# psc3_p8_ppca register map
Vendor: Infineon Technologies; Series: PSC3_P8; File version: 1.0
CPU: CM33 r0p1, little endian, MPU, FPU, DSP, VTOR, 3 interrupt priority bits, 143 interrupts
Registers are 32-bit, read-write, reset 0x0 unless marked. A register's access mark holds for its fields unless they carry their own. Offsets are from the block's base; [hi:lo] are bit positions; lines under a group give offsets from that group; {n}, {i} and the like mark numbered series; 'fields as' and 'values as' point back to an identical list; <NAME> marks a mode.

## PPCA_ATOPSS_DCSG_GRP0
Base 0x43588000
Same registers: PPCA_ATOPSS_DCSG_GRP1 0x4358A000
0x00 DCSG group
  {0x0+0x100*j} SLICE[{j}] (j=0..5) group — DCSG Slice Module
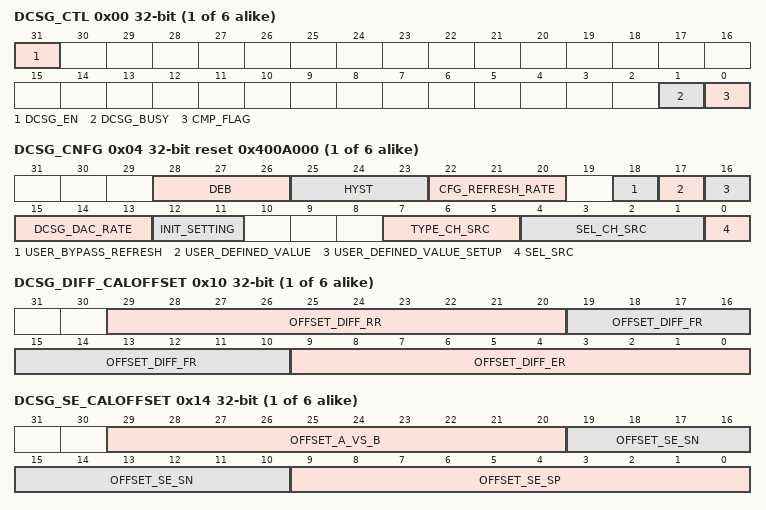
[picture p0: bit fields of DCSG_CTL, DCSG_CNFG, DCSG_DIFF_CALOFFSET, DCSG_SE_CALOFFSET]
    0x00 DCSG_CTL — Analog Comparator Control Register
      [31] DCSG_EN — Enable/Disable Analog Comparator 0 = Disable (power down) 1 = Enable
      [1] DCSG_BUSY ro — DCSG Busy: 1 = Busy 0 = Idle
      [0] CMP_FLAG ro — Reflects status of the COMP_OUT signal 0 = Input <= Configured Threshold 1 = Input > Configured Threshold
    0x04 DCSG_CNFG reset 0x400A000 — Analog Comparator Configuration Register
      [28:26] DEB — Debounce feature for HYST operation (Only for A_VS_B Mode Hysteresis )
        0=Debounce feature is disabled; 1=Transistion must be valid for 2 clock cycle; {v}=Transition must be valid for {v+1} clock cycle (v=2..7)
      [25:23] HYST — Hysteresis setup for A_VS_B Mode. 1 LSB is equivalent to 1.6mV
        0=Hysteresis feature is disabled; 1=+/- 1 LSB hysteresis is introduced; 2=+/- 2 LSB hysteresis is introduced; 3=+/- 4 LSB hysteresis is introduced; 4=+/- 8 LSB hysteresis is introduced; 5=+/- 16 LSB hysteresis is introduced; 6=+/- 32 LSB hysteresis is introduced; 7=+/- 64 LSB hysteresis is introduced
      [22:20] CFG_REFRESH_RATE — Refresh Rate Setting for Internal INIT. To compute the refresh rate duration, please use the following formula. 1/DCSG_CLK*Clk counter value
        0=10000 Clk counter -> 50.0usec based on 200MHz Clock; 1=7500 Clk counter -> 37.5usec based on 200MHz Clock; 2=5000 Clk counter -> 25.0usec based on 200MHz Clock; 3=3500 Clk counter -> 17.5usec based on 200MHz Clock; 4=2500 Clk counter -> 12.5usec based on 200MHz Clock; 5=1750 Clk counter -> 8.75usec based on 200MHz Clock; 6=1250 Clk counter -> 6.25usec based on 200MHz Clock; 7=1000 Clk counter -> 5.00usec based on 200MHz Clock
      [18] USER_BYPASS_REFRESH — BYPASS_REFRESH 0 - No Bypass 1 - Bypass. When bypass and in USER_DEFINED_VALUE_SETUP, USER defined value will be drive the CMP_FLAG
      [17] USER_DEFINED_VALUE
      [16] USER_DEFINED_VALUE_SETUP — To use User Defined Value during Refresh 0 - CMP_FLAG from comparator output 1 - CMP_FLAG from user default value
      [15:13] DCSG_DAC_RATE — To configurate the DCSG DAC update rate (Based on 200MHz Clock) 0 - 4 Clock Cycle, 0 tblank clk cycle (This is only for slope gen only) 1 - 4 Clock Cycle, 2 tblank clk cycle (This is only for slope gen only) 2 - 4 Clock Cycle, 3 tblank clk cycle (This is only for slope gen only) 3 - 6 Clock Cycle, 4 tblank clk cycle 4 - 8 Clock Cycle, 6 tblank clk cycle 5 - 10 Clock Cycle, 8 tblank clk cycle 6 - 12 Clock Cycle, 10 tblank clk cycle 7 - 20 Clock Cycle, 18 tblank clk cycle
      [12:11] INIT_SETTING — To configure the blanking period of DCSG during initization
        0=BLANK_8 (Blanking period is 8 after init. It will be 98 if used with SEL_SRC=1); 1=BLANK_10_1 (Blanking period is 10 after init. It will be 98 if used with SEL_SRC=1); 2=BLANK_10_2 (Blanking period is 10 after init. It will be 98 if used with SEL_SRC=1); 3=BLANK_12 (Blanking period is 12 after init. It will be 98 if used with SEL_SRC=1)
      [7:5] TYPE_CH_SRC — Select between Differential or Single Ended or A_vs_B
        0=TYPE_CH_DIFF_ER (Differential Mode Full Range support +/-3.3V. Other than 5, this will be selected); 1=TYPE_CH_DIFF_FR (Differential Mode Full Range support 0-3.3V); 2=TYPE_CH_SINGLE_P (Single-Ended Mode P Vs GND (Use together with SEL_CH_SRC)); 3=TYPE_CH_SINGLE_N (Single-Ended Mode N Vs GND (User together with SEL_CH_SRC)); 4=TYPE_CH_DIFF_RR (Differential Mode Full Range support +/-200mV); 5=TYPE_CH_A_vs_B (A vs B Mode)
      [4:1] SEL_CH_SRC — Select Analog Input Channel Source 0 = CH 0 1 = CH 1 ... 11 = CH 11
      [0] SEL_SRC — Select between Internal (DAC R2R) or External Source (Analog input Channel) 0 = External (From Analog Input Pad) 1 = Internal (From DAC R2R Output)
    0x08 DCSG_TH — Analog Comparator Threshold configuration register
      [11:0] TH — DCSG Threshold register. User shall ensure that DCSG_BUSY bit is '0' when performing write operation on this register. Please take note that if user is using SLGEN, user should observe the DCSG_SLGEN_CTL.SLGEN_BUSY.
    0x10 DCSG_DIFF_CALOFFSET — Analog Comparator Differential Mode Calibration register
      [29:20] OFFSET_DIFF_RR — Signed offset calibration value for sampler in differential mode in DIFF_RR
      [19:10] OFFSET_DIFF_FR — Signed offset calibration value for sampler in differential mode in DIFF_FR
      [9:0] OFFSET_DIFF_ER — Signed offset calibration value for sampler in differential mode in DIFF_ER
    0x14 DCSG_SE_CALOFFSET — Analog Comparator Single Ended Mode Calibration register
      [29:20] OFFSET_A_VS_B — Signed offset calibration value for sampler in A vs B mode
      [19:10] OFFSET_SE_SN — Signed offset calibration value for sampler in single ended N mode
      [9:0] OFFSET_SE_SP — Signed offset calibration value for sampler in single ended P mode
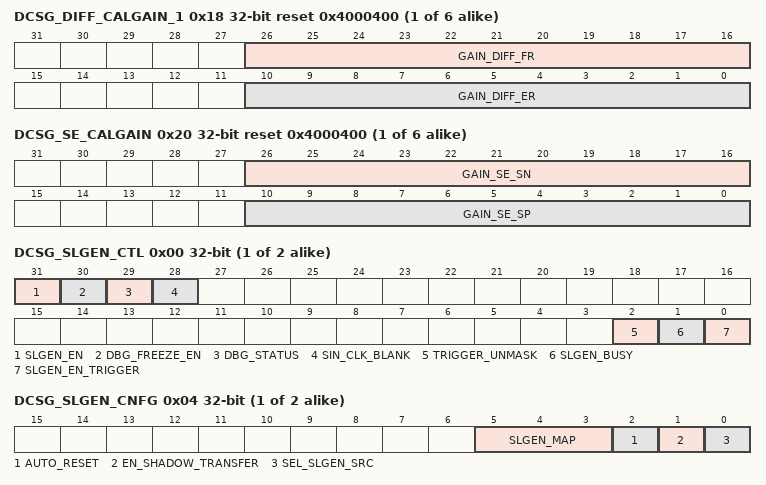
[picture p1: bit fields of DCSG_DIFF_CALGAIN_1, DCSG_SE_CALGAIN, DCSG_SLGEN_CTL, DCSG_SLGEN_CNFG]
    0x18 DCSG_DIFF_CALGAIN_1 reset 0x4000400 — Analog Comparator Differential Mode Gain register
      [26:16] GAIN_DIFF_FR — Signed gain calibration value for sampler in differential mode in DIFF_FR
      [10:0] GAIN_DIFF_ER — Signed gain calibration value for sampler in differential mode in DIFF_ER
    0x1C DCSG_DIFF_CALGAIN_2 reset 0x400 — Analog Comparator Differential Mode Gain register
      [10:0] GAIN_DIFF_RR — Signed gain calibration value for sampler in differential mode in DIFF_RR
    0x20 DCSG_SE_CALGAIN reset 0x4000400 — Analog Comparator Single Ended Mode Gain register
      [26:16] GAIN_SE_SN — Signed gain calibration value for sampler in single ended N mode
      [10:0] GAIN_SE_SP — Signed gain calibration value for sampler in single ended P mode
  {0x600+0x100*j} SLGEN[{j}] (j=0..1) group — DCSG Slice Module
    0x00 DCSG_SLGEN_CTL
      [31] SLGEN_EN — Enable/Disable Slope Generator 0 = Disable (under reset) 1 = Enable
      [30] DBG_FREEZE_EN — Specifies the slope generator behavior in debug mode. '0': When ='0', slope generator operation continues or resume '1': When ='1', slope generator freeze the operation immediately
      [29] DBG_STATUS ro — Specifies whether SLGEN has enter into Debug state 1 = Yes 2 = No
      [28] SIN_CLK_BLANK — Single Clock Blank 0 - Enabled 1 - Disabled
      [2] TRIGGER_UNMASK — Trigger mask/unmask function 0 = Trigger are masked. Upon detect of trigger will not start the SL operation 1 = Trigger are unmasked. Upon detect of Trigger will start the SL operation
      [1] SLGEN_BUSY ro — Report Slope Generator status 0 = free 1 = busy (in operation)
      [0] SLGEN_EN_TRIGGER — Trigger Slope Generator function 0 = Do nothing 1 = Trigger ramp generation
    0x04 DCSG_SLGEN_CNFG
      [5:3] SLGEN_MAP — To map SL_GEN operation DCSG
        {v}=SL_GEN is configured to DCSG_{v} (v=0..5)
      [2] AUTO_RESET — Auto-Reset of Slope Generation threshold between initial and target value. This will work with all the setting of DUR_SLGEN_TH_ADJ 0 - AUTORESET OFF 1 - AUTORESET ON
      [1] EN_SHADOW_TRANSFER — Enable Shadow Transfer Feature 0 = Shadow Transfer Feature Disable 1 = Shadow Transfer Feature Enable
      [0] SEL_SLGEN_SRC — Select Slope Generator source for DAC register 0 = CPU is in control of DCSG_TH register DAC threshold 1 = Select SLGEN RAMP as source, SLGEN_RAMP is control of the DAC threshold
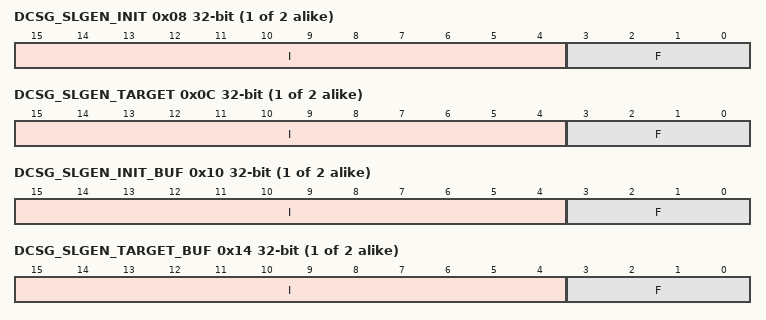
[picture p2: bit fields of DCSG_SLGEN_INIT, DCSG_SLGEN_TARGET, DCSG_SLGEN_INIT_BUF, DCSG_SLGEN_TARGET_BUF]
    0x08 DCSG_SLGEN_INIT
      [15:4] I — Initial Set Integer Value
      [3:0] F — Initial Set Fractional Value
    0x0C DCSG_SLGEN_TARGET
      [15:4] I — Target Set Integer Value
      [3:0] F — Target Set Fractional Value
    0x10 DCSG_SLGEN_INIT_BUF
      fields as DCSG.SLGEN[0].DCSG_SLGEN_INIT
    0x14 DCSG_SLGEN_TARGET_BUF
      fields as DCSG.SLGEN[0].DCSG_SLGEN_TARGET
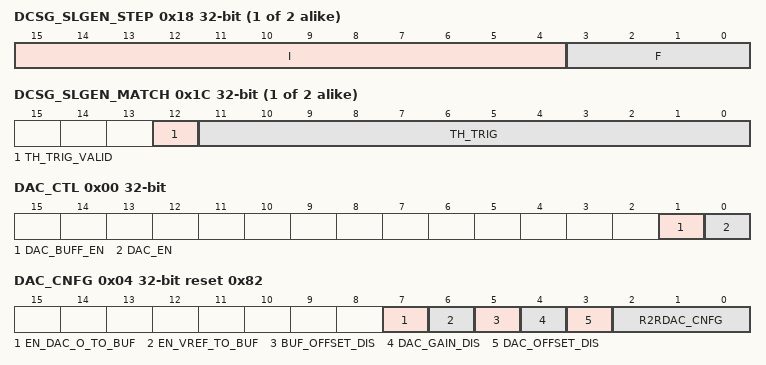
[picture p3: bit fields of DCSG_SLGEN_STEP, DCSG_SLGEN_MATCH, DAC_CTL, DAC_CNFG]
    0x18 DCSG_SLGEN_STEP
      [15:4] I — Step Integer Value
      [3:0] F — Step Fractional Value
    0x1C DCSG_SLGEN_MATCH ro
      [12] TH_TRIG_VALID — Indicate if the reported TH_TRIG is occurred after the provide Slope Start 0: reported value occurred before trigger 1: reported value occurred after trigger
      [11:0] TH_TRIG — Reports the slope value at which the comparator triggered
  0xC00 BLANK group — DCSG Slice Module
    0x00 DCSG_BLANK_CTL
      [31] DCSG_BLANK_EN — Enable/Disable Blanking support for Analog Comparator 0 = Disable (power down) 1 = Enable
0x1000 DAC_R2R group — CSG Module
  0x00 DAC_CTL
    [1] DAC_BUFF_EN — Enable/Disable DAC BUF 0 = Disable (powered down) 1 = Enable (powered up)
    [0] DAC_EN — Enable/Disable DAC 0 = Disable (powered down) 1 = Enable (powered up)
  0x04 DAC_CNFG reset 0x82
    [7] EN_DAC_O_TO_BUF — For ADFT Purpose - Enable DAC_Output as reference to Buffer 0 - DAC_Output is not connected as reference 1 - DAC_Output is connected as reference
    [6] EN_VREF_TO_BUF — For ADFT Purpose - Enable VREF as reference to Buffer 0 - VREF is not connected as reference 1 - VREF is connected as reference
    [5] BUF_OFFSET_DIS — BUFF Offset correction. Correction is added to DOUT value before sending to R2R_DAC Analog module 0 - Buffer Offset correction is enabled 1 - Buffer Offset correction is disabled
    [4] DAC_GAIN_DIS — DAC Gain correction. Correction is added to DOUT value before sending to R2R_DAC Analog module 0 - Gain Offset correction is enabled 1 - Gain Offset correction is disabled
    [3] DAC_OFFSET_DIS — DAC Offset correction. Correction is added to DOUT value before sending to R2R_DAC Analog module 0 - DAC Offset correction is enabled 1 - DAC Offset correction is disabled
    [2:0] R2RDAC_CNFG — R2R DAC Configuration
      0=Single Ended Mode Full Range from 0V to 0.4V (NA); 1=Loopback Single Ended Mode (P-G) from 0V to 3.3V) Loopback Differential Mode (P-N) from 0V to 3.3V); 2=DAC Buffer with 1.2 Full Range; 3=DAC Buffer with VDDA/2 Full Range; 4=Loopback Differential Mode (VDDREF=0.4V, from -0.2V to 0.2V); 5=Loopback Differential Mode (VDDREF=VDDA, from -3.3V to 3.3V); 6=DAC Buffer with 1.2 Full Range (NA); 7=DAC Buffer with VDDA/2 Full Range (NA)
  0x08 DAC_DOUT
    [11:0] DOUT — DAC Data Output
  0x0C DAC_OFFSET_CNFG1
    [9:0] DAC_OFFSET_CNFG1 — Signed offset calibration value for CNFG1
  0x10 DAC_OFFSET_CNFG2 — DAC Gain CNFG4 register
    [9:0] DAC_OFFSET_CNFG2 — Signed offset calibration value for CNFG2
  {0x8+4j} DAC_OFFSET_CNFG{j} (j=3..5) — 0
    [9:0] DAC_OFFSET_CNFG{j} — Signed offset calibration value for CNFG{j}
  {0x1C+4j} DAC_GAIN_CNFG{j} reset 0x400 (j=1..5)
    [10:0] DAC_GAIN_CNFG{j}
  0x34 BUFFER_OFFSET_1
    [9:0] BUFFER_OFFSET_1 — Signed offset calibration value for Buffer in 1.2 Full Range
  0x38 BUFFER_OFFSET_2
    [9:0] BUFFER_OFFSET_2 — Signed offset calibration value for Buffer in VDDA/2 Full Range
